AUTOSAR XML (schema 00054)
package /SwComponentTypes
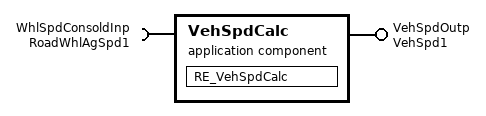
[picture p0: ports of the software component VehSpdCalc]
  application sw component type VehSpdCalc
    require port WhlSpdConsoldInp: nonqueued-receiver-com-spec{data-element=RoadWhlAgSpd, init-value=Default_WhlSpdConsoldInp:0}, required-interface=RoadWhlAgSpd1
    provide port VehSpdOutp: provided-interface=VehSpd1
    behavior VehSpdCalc_IB: data-type-mapping=[DataTypeMappingSet_AgSpd, DataTypeMappingSet_Spd], supports-multiple-instantiation=true
      data received event DRE_WhlSpdConsoldInp: start-on-event=RE_VehSpdCalc, data=WhlSpdConsoldInp.RoadWhlAgSpd
      runnable RE_VehSpdCalc: minimum-start-interval=0.01
        data-receive-point-by-arguments:
          access DRPA_WhlSpdConsoldInp: accessed-variable=WhlSpdConsoldInp.RoadWhlAgSpd
        data-write-access:
          access DWA_VehSpdOutp: accessed-variable=VehSpdOutp.VehSpd
